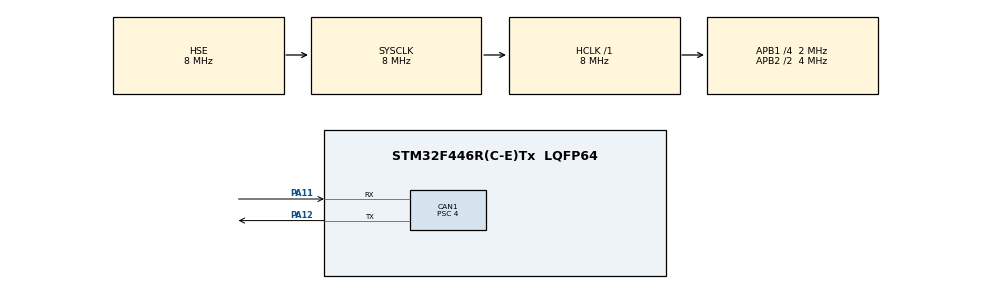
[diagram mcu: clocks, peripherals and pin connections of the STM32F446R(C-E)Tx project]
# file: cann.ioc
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CAN1.ABOM=ENABLE
CAN1.BS1=CAN_BS1_8TQ
CAN1.CalculateBaudRate=50000
CAN1.CalculateTimeBit=20000
CAN1.CalculateTimeQuantum=2000.0
CAN1.NART=ENABLE
CAN1.Prescaler=4
Mcu.Family=STM32F4
Mcu.Name=STM32F446R(C-E)Tx
Mcu.Package=LQFP64
NVIC.CAN1_RX0_IRQn=true\:0\:0\:false\:false\:true\:true\:true\:true
NVIC.PriorityGroup=NVIC_PRIORITYGROUP_0
PA11.Mode=CAN_Activate
PA11.Signal=CAN1_RX
PA12.Mode=CAN_Activate
PA12.Signal=CAN1_TX
PC14-OSC32_IN.Mode=LSE-External-Oscillator
PC14-OSC32_IN.Signal=RCC_OSC32_IN
PC15-OSC32_OUT.Mode=LSE-External-Oscillator
PC15-OSC32_OUT.Signal=RCC_OSC32_OUT
PH0-OSC_IN.Mode=HSE-External-Oscillator
PH0-OSC_IN.Signal=RCC_OSC_IN
PH1-OSC_OUT.Mode=HSE-External-Oscillator
PH1-OSC_OUT.Signal=RCC_OSC_OUT
ProjectManager.HeapSize=0x200
ProjectManager.StackSize=0x400
ProjectManager.TargetToolchain=STM32CubeIDE
RCC.48MHZClocksFreq_Value=84000000
RCC.AHBFreq_Value=8000000
RCC.APB1CLKDivider=RCC_HCLK_DIV4
RCC.APB1Freq_Value=2000000
RCC.APB1TimFreq_Value=4000000
RCC.APB2CLKDivider=RCC_HCLK_DIV2
RCC.APB2Freq_Value=4000000
RCC.APB2TimFreq_Value=8000000
RCC.CortexFreq_Value=8000000
RCC.FLatency-AdvancedSettings=FLASH_LATENCY_0
RCC.HCLKFreq_Value=8000000
RCC.HSE_VALUE=8000000
RCC.HSI_VALUE=16000000
RCC.PLLM=4
RCC.PLLN=180
RCC.PLLSourceVirtual=RCC_PLLSOURCE_HSE
RCC.SYSCLKFreq_VALUE=8000000
RCC.SYSCLKSource=RCC_SYSCLKSOURCE_HSE
RCC.USBFreq_Value=180000000
RCC.VCOOutputFreq_Value=360000000
board=NUCLEO-F446RE

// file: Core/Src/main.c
/* USER CODE BEGIN Header */
/**
  ******************************************************************************
  * @file           : main.c
  * @brief          : Main program body
  ******************************************************************************
  * @attention
  *
  * Copyright (c) 2022 STMicroelectronics.
  * All rights reserved.
  *
  * This software is licensed under terms that can be found in the LICENSE file
  * in the root directory of this software component.
  * If no LICENSE file comes with this software, it is provided AS-IS.
  *
  ******************************************************************************
  */
/* USER CODE END Header */
#include "main.h"

CAN_HandleTypeDef hcan1;

/* USER CODE BEGIN PV */
CAN_FilterTypeDef canFilter1;
CAN_RxHeaderTypeDef can1RxHeader;
CAN_TxHeaderTypeDef can1TxHeader;

uint8_t can1Rx0Data[8];
uint32_t TxMailBox1;
uint8_t can1Tx0Data[8];
/* USER CODE END PV */

void SystemClock_Config(void);
static void MX_GPIO_Init(void);
static void MX_CAN1_Init(void);
/* USER CODE BEGIN PFP */
void HAL_CAN_RxFifo0MsgPendingCallback(CAN_HandleTypeDef *hcan);
void CAN_Filter_Init(void);
void CAN_Send(uint8_t ID, uint8_t data0, uint8_t data1, uint8_t data2, uint8_t data3, uint8_t data4, uint8_t data5, uint8_t data6, uint8_t data7);
void CAN_SendAll(void);
/* USER CODE END PFP */

int main(void)
{

  /* MCU Configuration--------------------------------------------------------*/

  /* Reset of all peripherals, Initializes the Flash interface and the Systick. */
  HAL_Init();

  /* Configure the system clock */
  SystemClock_Config();

  /* Initialize all configured peripherals */
  MX_GPIO_Init();
  MX_CAN1_Init();

  /* Infinite loop */
  /* USER CODE BEGIN WHILE */
  while (1)
  {
	  CAN_Send(0x10, 0, 0, 0, 0, 0, 0, 0, 0);
	  HAL_Delay(50);
    /* USER CODE END WHILE */

  }
}

void SystemClock_Config(void)
{
  RCC_OscInitTypeDef RCC_OscInitStruct = {0};
  RCC_ClkInitTypeDef RCC_ClkInitStruct = {0};

  /** Configure the main internal regulator output voltage
  */
  __HAL_RCC_PWR_CLK_ENABLE();
  __HAL_PWR_VOLTAGESCALING_CONFIG(PWR_REGULATOR_VOLTAGE_SCALE3);

  /** Initializes the RCC Oscillators according to the specified parameters
  * in the RCC_OscInitTypeDef structure.
  */
  RCC_OscInitStruct.OscillatorType = RCC_OSCILLATORTYPE_HSE;
  RCC_OscInitStruct.HSEState = RCC_HSE_ON;
  RCC_OscInitStruct.PLL.PLLState = RCC_PLL_NONE;
  if (HAL_RCC_OscConfig(&RCC_OscInitStruct) != HAL_OK)
  {
    Error_Handler();
  }

  /** Initializes the CPU, AHB and APB buses clocks
  */
  RCC_ClkInitStruct.ClockType = RCC_CLOCKTYPE_HCLK|RCC_CLOCKTYPE_SYSCLK
                              |RCC_CLOCKTYPE_PCLK1|RCC_CLOCKTYPE_PCLK2;
  RCC_ClkInitStruct.SYSCLKSource = RCC_SYSCLKSOURCE_HSE;
  RCC_ClkInitStruct.AHBCLKDivider = RCC_SYSCLK_DIV1;
  RCC_ClkInitStruct.APB1CLKDivider = RCC_HCLK_DIV4;
  RCC_ClkInitStruct.APB2CLKDivider = RCC_HCLK_DIV2;

  if (HAL_RCC_ClockConfig(&RCC_ClkInitStruct, FLASH_LATENCY_0) != HAL_OK)
  {
    Error_Handler();
  }
}

static void MX_CAN1_Init(void)
{

  hcan1.Instance = CAN1;
  hcan1.Init.Prescaler = 4;
  hcan1.Init.Mode = CAN_MODE_NORMAL;
  hcan1.Init.SyncJumpWidth = CAN_SJW_1TQ;
  hcan1.Init.TimeSeg1 = CAN_BS1_8TQ;
  hcan1.Init.TimeSeg2 = CAN_BS2_1TQ;
  hcan1.Init.TimeTriggeredMode = DISABLE;
  hcan1.Init.AutoBusOff = ENABLE;
  hcan1.Init.AutoWakeUp = DISABLE;
  hcan1.Init.AutoRetransmission = ENABLE;
  hcan1.Init.ReceiveFifoLocked = DISABLE;
  hcan1.Init.TransmitFifoPriority = DISABLE;
  if (HAL_CAN_Init(&hcan1) != HAL_OK)
  {
    Error_Handler();
  }
  /* USER CODE BEGIN CAN1_Init 2 */
  CAN_Filter_Init();
  /* USER CODE END CAN1_Init 2 */

}

static void MX_GPIO_Init(void)
{

  /* GPIO Ports Clock Enable */
  __HAL_RCC_GPIOC_CLK_ENABLE();
  __HAL_RCC_GPIOH_CLK_ENABLE();
  __HAL_RCC_GPIOA_CLK_ENABLE();

}

/* USER CODE BEGIN 4 */
void CAN_Filter_Init(void)
{
	canFilter1.FilterMaskIdHigh = 0x000 << 5; // Shift 5 bit
	canFilter1.FilterIdHigh = 0x000 << 5;
	canFilter1.FilterMaskIdLow = 0x000 << 5; // Shift 5 bit
	canFilter1.FilterIdLow = 0x000 << 5;
	canFilter1.FilterMode = CAN_FILTERMODE_IDMASK;
	canFilter1.FilterScale = CAN_FILTERSCALE_16BIT;
	canFilter1.FilterFIFOAssignment = CAN_FILTER_FIFO0;
	canFilter1.FilterBank = 0;
	canFilter1.FilterActivation = ENABLE;

	/* Set options for messages; ID type(standard), Length(8 byte) */
	can1TxHeader.RTR = CAN_RTR_DATA;
	can1TxHeader.IDE = CAN_ID_STD;
	can1TxHeader.DLC = 8;

	HAL_CAN_ConfigFilter(&hcan1, &canFilter1);
	HAL_CAN_ActivateNotification(&hcan1, CAN_IT_RX_FIFO0_MSG_PENDING);
	HAL_CAN_Start(&hcan1);
}

void CAN_Send(uint8_t ID, uint8_t data0, uint8_t data1, uint8_t data2, uint8_t data3, uint8_t data4, uint8_t data5, uint8_t data6, uint8_t data7)
{
	  /* Set options for messages; Address */
	  can1TxHeader.StdId = ID;

	  can1Tx0Data[7] = data7;
	  can1Tx0Data[6] = data6;
	  can1Tx0Data[5] = data5;
	  can1Tx0Data[4] = data4;
	  can1Tx0Data[3] = data3;
	  can1Tx0Data[2] = data2;
	  can1Tx0Data[1] = data1;
	  can1Tx0Data[0] = data0;

	  HAL_CAN_AddTxMessage(&hcan1, &can1TxHeader, &can1Tx0Data[0], &TxMailBox1);
}

void CAN_SendAll(void) {
	;
}

/* Receiving CAN Data */
/* Get CAN1 message Through FIFO0 */
void HAL_CAN_RxFifo0MsgPendingCallback(CAN_HandleTypeDef *hcan)
{
	HAL_CAN_GetRxMessage(&hcan1, CAN_RX_FIFO0, &can1RxHeader, can1Rx0Data);
	printf("yes\r\n");
}
/* USER CODE END 4 */

void Error_Handler(void)
{
  __disable_irq();
  while (1)
  {
  }
}
